AUTOSAR XML (schema 00046)
package /ComponentTypes
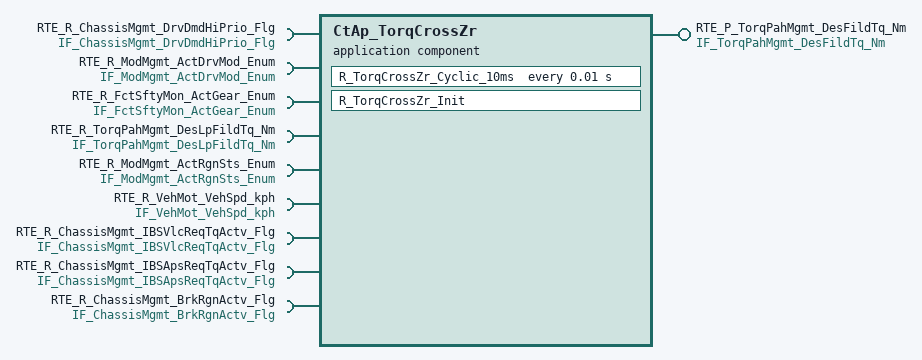
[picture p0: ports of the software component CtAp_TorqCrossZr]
  application sw component type CtAp_TorqCrossZr
    provide port RTE_P_TorqPahMgmt_DesFildTq_Nm: nonqueued-sender-com-spec{data-element=tec_TorqPahMgmt_DesFildTq_Nm, init-value=0}, provided-interface=IF_TorqPahMgmt_DesFildTq_Nm
    9 x require port:
      RTE_R_ChassisMgmt_DrvDmdHiPrio_Flg: nonqueued-receiver-com-spec{data-element=tec_ChassisMgmt_DrvDmdHiPrio_Flg, filter=data-filter-type=ALWAYS, init-value=0}, required-interface=IF_ChassisMgmt_DrvDmdHiPrio_Flg
      RTE_R_ModMgmt_ActDrvMod_Enum: nonqueued-receiver-com-spec{data-element=tec_ModMgmt_ActDrvMod_Enum, filter=data-filter-type=ALWAYS, init-value=0}, required-interface=IF_ModMgmt_ActDrvMod_Enum
      RTE_R_FctSftyMon_ActGear_Enum: nonqueued-receiver-com-spec{data-element=tec_FctSftyMon_ActGear_Enum, filter=data-filter-type=ALWAYS, init-value=0}, required-interface=IF_FctSftyMon_ActGear_Enum
      RTE_R_TorqPahMgmt_DesLpFildTq_Nm: nonqueued-receiver-com-spec{data-element=tec_TorqPahMgmt_DesLpFildTq_Nm, filter=data-filter-type=ALWAYS, init-value=0}, required-interface=IF_TorqPahMgmt_DesLpFildTq_Nm
      RTE_R_ModMgmt_ActRgnSts_Enum: nonqueued-receiver-com-spec{data-element=tec_ModMgmt_ActRgnSts_Enum, filter=data-filter-type=ALWAYS, init-value=0}, required-interface=IF_ModMgmt_ActRgnSts_Enum
      RTE_R_VehMot_VehSpd_kph: nonqueued-receiver-com-spec{data-element=tec_VehMot_VehSpd_kph, filter=data-filter-type=ALWAYS, init-value=0}, required-interface=IF_VehMot_VehSpd_kph
      RTE_R_ChassisMgmt_IBSVlcReqTqActv_Flg: nonqueued-receiver-com-spec{data-element=tec_ChassisMgmt_IBSVlcReqTqActv_Flg, filter=data-filter-type=ALWAYS, init-value=0}, required-interface=IF_ChassisMgmt_IBSVlcReqTqActv_Flg
      RTE_R_ChassisMgmt_IBSApsReqTqActv_Flg: nonqueued-receiver-com-spec{data-element=tec_ChassisMgmt_IBSApsReqTqActv_Flg, filter=data-filter-type=ALWAYS, init-value=0}, required-interface=IF_ChassisMgmt_IBSApsReqTqActv_Flg
      RTE_R_ChassisMgmt_BrkRgnActv_Flg: nonqueued-receiver-com-spec{data-element=tec_ChassisMgmt_BrkRgnActv_Flg, filter=data-filter-type=ALWAYS}, required-interface=IF_ChassisMgmt_BrkRgnActv_Flg
    behavior CtAp_TorqCrossZr_InternalBehavior
      timing event TMT_R_TorqCrossZr_Cyclic_10ms: start-on-event=R_TorqCrossZr_Cyclic_10ms, period=0.01
      init event CtAp_TorqCrossZr_InitEvent: start-on-event=R_TorqCrossZr_Init
      runnable R_TorqCrossZr_Cyclic_10ms
        data-receive-point-by-arguments:
          9 x access:
            REC_RTE_R_ChassisMgmt_DrvDmdHiPrio_Flg_tec_ChassisMgmt_DrvDmdHiPrio_Flg: accessed-variable=RTE_R_ChassisMgmt_DrvDmdHiPrio_Flg.tec_ChassisMgmt_DrvDmdHiPrio_Flg
            REC_RTE_R_FctSftyMon_ActGear_Enum_tec_FctSftyMon_ActGear_Enum: accessed-variable=RTE_R_FctSftyMon_ActGear_Enum.tec_FctSftyMon_ActGear_Enum
            REC_RTE_R_ModMgmt_ActDrvMod_Enum_tec_ModMgmt_ActDrvMod_Enum: accessed-variable=RTE_R_ModMgmt_ActDrvMod_Enum.tec_ModMgmt_ActDrvMod_Enum
            REC_RTE_R_ModMgmt_ActRgnSts_Enum_tec_ModMgmt_ActRgnSts_Enum: accessed-variable=RTE_R_ModMgmt_ActRgnSts_Enum.tec_ModMgmt_ActRgnSts_Enum
            REC_RTE_R_TorqPahMgmt_DesLpFildTq_Nm_tec_TorqPahMgmt_DesLpFildTq_Nm: accessed-variable=RTE_R_TorqPahMgmt_DesLpFildTq_Nm.tec_TorqPahMgmt_DesLpFildTq_Nm
            REC_RTE_R_VehMot_VehSpd_kph_tec_VehMot_VehSpd_kph: accessed-variable=RTE_R_VehMot_VehSpd_kph.tec_VehMot_VehSpd_kph
            REC_RTE_R_ChassisMgmt_IBSApsReqTqActv_Flg_tec_ChassisMgmt_IBSApsReqTqActv_Flg: accessed-variable=RTE_R_ChassisMgmt_IBSApsReqTqActv_Flg.tec_ChassisMgmt_IBSApsReqTqActv_Flg
            REC_RTE_R_ChassisMgmt_IBSVlcReqTqActv_Flg_tec_ChassisMgmt_IBSVlcReqTqActv_Flg: accessed-variable=RTE_R_ChassisMgmt_IBSVlcReqTqActv_Flg.tec_ChassisMgmt_IBSVlcReqTqActv_Flg
            REC_RTE_R_ChassisMgmt_BrkRgnActv_Flg_tec_ChassisMgmt_BrkRgnActv_Flg: accessed-variable=RTE_R_ChassisMgmt_BrkRgnActv_Flg.tec_ChassisMgmt_BrkRgnActv_Flg
        data-send-points:
          access SEND_RTE_P_TorqPahMgmt_DesFildTq_Nm_tec_TorqPahMgmt_DesFildTq_Nm: accessed-variable=RTE_P_TorqPahMgmt_DesFildTq_Nm.tec_TorqPahMgmt_DesFildTq_Nm
      runnable R_TorqCrossZr_Init
  swc implementation CtAp_TorqCrossZr_Implementation: behavior=CtAp_TorqCrossZr_InternalBehavior
